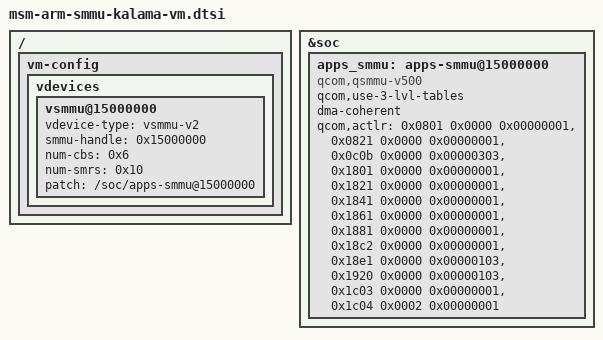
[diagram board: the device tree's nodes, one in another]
#include <dt-bindings/interrupt-controller/arm-gic.h>

/ {
	vm-config {
		vdevices {
			vsmmu@15000000 {
				vdevice-type = "vsmmu-v2";
				smmu-handle = <0x15000000>;
				num-cbs = <0x6>;
				num-smrs = <0x10>;
				patch = "/soc/apps-smmu@15000000";
			};
		};
	};
};

&soc {
	apps_smmu: apps-smmu@15000000 {
		/*
		 * reg, #global-interrupts & interrupts  properties will
		 * be added dynamically by bootloader.
		 */
		compatible = "qcom,qsmmu-v500", "qcom,virt-smmu";
		#iommu-cells = <2>;
		qcom,use-3-lvl-tables;
		dma-coherent;
		qcom,actlr =
			/* Camera IFE and SFE */
			<0x0801 0x0000 0x00000001>,
			<0x0821 0x0000 0x00000001>,

			/* Compute */
			<0x0c0b 0x0000 0x00000303>,

			/* Camera IPE, BPS, CDM IPE, CDM IFE, CDM BPS, ICP */
			<0x1801 0x0000 0x00000001>,
			<0x1821 0x0000 0x00000001>,
			<0x1841 0x0000 0x00000001>,
			<0x1861 0x0000 0x00000001>,
			<0x1881 0x0000 0x00000001>,
			<0x18c2 0x0000 0x00000001>,

			/* Camera CRE */
			<0x18e1 0x0000 0x00000103>,

			/* EVA */
			<0x1920 0x0000 0x00000103>,

			/* Display */
			<0x1c03 0x0000 0x00000001>,
			<0x1c04 0x0002 0x00000001>;
	};
};
